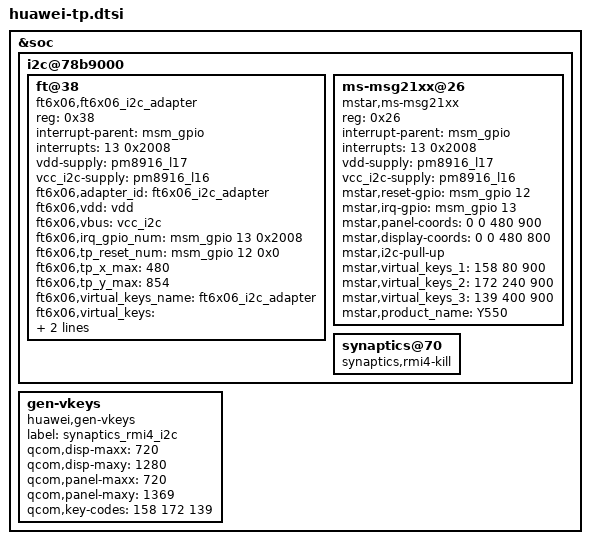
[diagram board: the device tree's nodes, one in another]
&soc {
	i2c@78b9000 { /* BLSP1 QUP5 */
		ft@38{
			compatible = "ft6x06,ft6x06_i2c_adapter";
			reg = <0x38>;
			interrupt-parent = <&msm_gpio>;
			interrupts = <13 0x2008>;
			vdd-supply = <&pm8916_l17>;
			vcc_i2c-supply = <&pm8916_l16>;
			ft6x06,adapter_id = "ft6x06_i2c_adapter";
			ft6x06,vdd = "vdd";
			ft6x06,vbus = "vcc_i2c";
			ft6x06,irq_gpio_num = <&msm_gpio 13 0x2008>;
			ft6x06,tp_reset_num = <&msm_gpio 12 0x0>;
			ft6x06,tp_x_max = <480>;
			ft6x06,tp_y_max = <854>;
			/* KeyCode CenterX CenterY Widght */
			ft6x06,virtual_keys_name = "ft6x06_i2c_adapter";
			ft6x06,virtual_keys = /* KeyCode CenterX CenterY Width Height */
				/* KEY_BACK */
				<158 40 900 80 62
				/* KEY_HOME(172) */
				172 240 900 80 62 
				/* KEY_MENU */
				139 400 900 80 62>;
                
            ft6x06,product_name = "Y550";
		};

		ms-msg21xx@26 {
			compatible = "mstar,ms-msg21xx";
			reg = <0x26>;
			interrupt-parent = <&msm_gpio>;
			interrupts = <13 0x2008>;
			vdd-supply = <&pm8916_l17>;
			vcc_i2c-supply = <&pm8916_l16>;
			
			mstar,reset-gpio = <&msm_gpio 12 0x0>;
			mstar,irq-gpio = <&msm_gpio 13 0x2008>;
			mstar,panel-coords = <0  0 480 900>;
			mstar,display-coords = <0 0 480 800>;
			mstar,i2c-pull-up;
			/* KeyCode CenterX CenterY */
			mstar,virtual_keys_1 = <158 80 900>;	/*back*/
			mstar,virtual_keys_2 = <172 240 900>;/*home*/
			mstar,virtual_keys_3 = <139 400 900>;/*menu*/
            
            mstar,product_name = "Y550";
		};
        
        synaptics@70 {
			compatible = "synaptics,rmi4-kill";
		};
	};
	/*To disable gen-vkeys.c probe,avoid generate kobject*/
	gen-vkeys {
		compatible = "huawei,gen-vkeys";
		label = "synaptics_rmi4_i2c";
		qcom,disp-maxx = <720>;
		qcom,disp-maxy = <1280>;
		qcom,panel-maxx = <720>;
		qcom,panel-maxy = <1369>;
		qcom,key-codes = <158 172 139>;
	};
};
